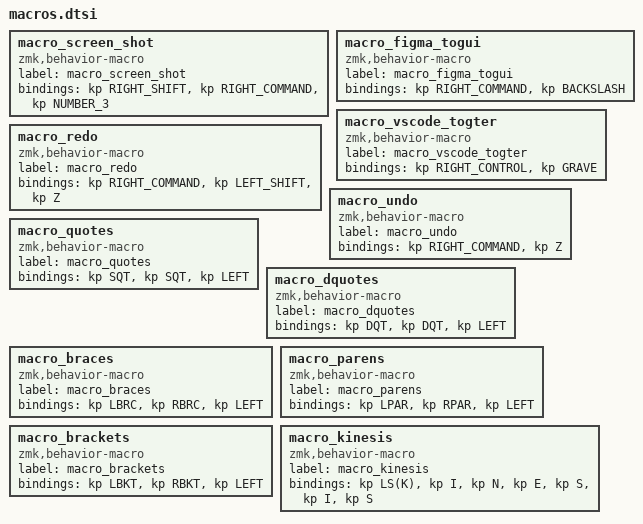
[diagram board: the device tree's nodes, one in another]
macro_screen_shot: macro_screen_shot{
compatible = "zmk,behavior-macro";
label = "macro_screen_shot";
#binding-cells = <0>;
bindings = <&kp RIGHT_SHIFT>, <&kp RIGHT_COMMAND>, <&kp NUMBER_3>;
};
macro_figma_togui: macro_figma_togui{
compatible = "zmk,behavior-macro";
label = "macro_figma_togui";
#binding-cells = <0>;
bindings = <&kp RIGHT_COMMAND>, <&kp BACKSLASH>;
};
macro_vscode_togter: macro_vscode_togter{
compatible = "zmk,behavior-macro";
label = "macro_vscode_togter";
#binding-cells = <0>;
bindings = <&kp RIGHT_CONTROL>, <&kp GRAVE>;
};
macro_redo: macro_redo{
compatible = "zmk,behavior-macro";
label = "macro_redo";
#binding-cells = <0>;
bindings = <&kp RIGHT_COMMAND>, <&kp LEFT_SHIFT>, <&kp Z>;
};
macro_undo: macro_undo{
compatible = "zmk,behavior-macro";
label = "macro_undo";
#binding-cells = <0>;
bindings = <&kp RIGHT_COMMAND>, <&kp Z>;
};
macro_quotes: macro_quotes{
compatible = "zmk,behavior-macro";
label = "macro_quotes";
#binding-cells = <0>;
bindings = <&kp SQT>, <&kp SQT>, <&kp LEFT>;
};
macro_dquotes: macro_dquotes{
compatible = "zmk,behavior-macro";
label = "macro_dquotes";
#binding-cells = <0>;
bindings = <&kp DQT>, <&kp DQT>, <&kp LEFT>;
};
macro_braces: macro_braces{
compatible = "zmk,behavior-macro";
label = "macro_braces";
#binding-cells = <0>;
bindings = <&kp LBRC>, <&kp RBRC>, <&kp LEFT>;
};
macro_parens: macro_parens{
compatible = "zmk,behavior-macro";
label = "macro_parens";
#binding-cells = <0>;
bindings = <&kp LPAR>, <&kp RPAR>, <&kp LEFT>;
};
macro_brackets: macro_brackets{
compatible = "zmk,behavior-macro";
label = "macro_brackets";
#binding-cells = <0>;
bindings = <&kp LBKT>, <&kp RBKT>, <&kp LEFT>;
};
macro_kinesis: macro_kinesis{
compatible = "zmk,behavior-macro";
label = "macro_kinesis";
#binding-cells = <0>;
bindings = <&kp LS(K)>, <&kp I>, <&kp N>, <&kp E>, <&kp S>, <&kp I>, <&kp S>;
};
